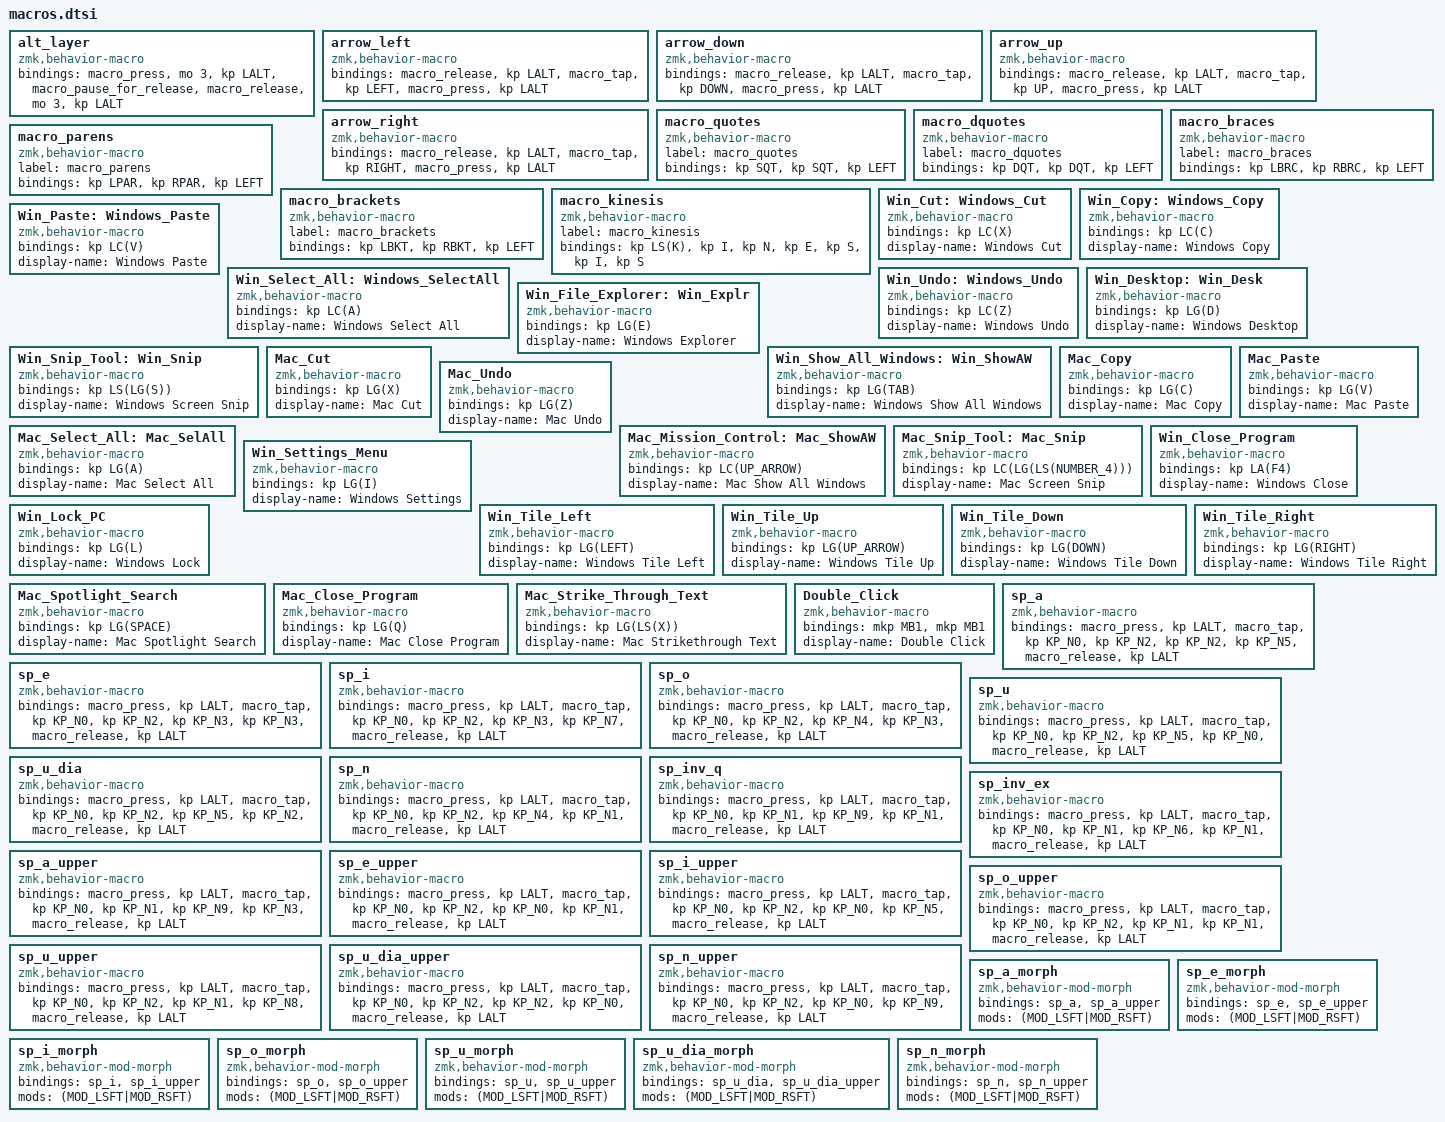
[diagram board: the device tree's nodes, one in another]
  // Alt + Layer 3 macro (holds Alt while layer is active)
  alt_layer: alt_layer {
    compatible = "zmk,behavior-macro";
    #binding-cells = <0>;
    bindings = <&macro_press &mo 3 &kp LALT>, <&macro_pause_for_release>, <&macro_release &mo 3 &kp LALT>;
  };

  // Arrow macros that release Alt, tap arrow, re-press Alt (for vim-style navigation)
  arrow_left: arrow_left {
    compatible = "zmk,behavior-macro";
    #binding-cells = <0>;
    bindings = <&macro_release &kp LALT>, <&macro_tap &kp LEFT>, <&macro_press &kp LALT>;
  };

  arrow_down: arrow_down {
    compatible = "zmk,behavior-macro";
    #binding-cells = <0>;
    bindings = <&macro_release &kp LALT>, <&macro_tap &kp DOWN>, <&macro_press &kp LALT>;
  };

  arrow_up: arrow_up {
    compatible = "zmk,behavior-macro";
    #binding-cells = <0>;
    bindings = <&macro_release &kp LALT>, <&macro_tap &kp UP>, <&macro_press &kp LALT>;
  };

  arrow_right: arrow_right {
    compatible = "zmk,behavior-macro";
    #binding-cells = <0>;
    bindings = <&macro_release &kp LALT>, <&macro_tap &kp RIGHT>, <&macro_press &kp LALT>;
  };

  macro_quotes: macro_quotes {
    compatible = "zmk,behavior-macro";
    label = "macro_quotes";
    #binding-cells = <0>;
    bindings = <&kp SQT>, <&kp SQT>, <&kp LEFT>;
  };
  macro_dquotes: macro_dquotes {
    compatible = "zmk,behavior-macro";
    label = "macro_dquotes";
    #binding-cells = <0>;
    bindings = <&kp DQT>, <&kp DQT>, <&kp LEFT>;
  };
  macro_braces: macro_braces {
    compatible = "zmk,behavior-macro";
    label = "macro_braces";
    #binding-cells = <0>;
    bindings = <&kp LBRC>, <&kp RBRC>, <&kp LEFT>;
  };
  macro_parens: macro_parens {
    compatible = "zmk,behavior-macro";
    label = "macro_parens";
    #binding-cells = <0>;
    bindings = <&kp LPAR>, <&kp RPAR>, <&kp LEFT>;
  };
  macro_brackets: macro_brackets {
    compatible = "zmk,behavior-macro";
    label = "macro_brackets";
    #binding-cells = <0>;
    bindings = <&kp LBKT>, <&kp RBKT>, <&kp LEFT>;
  };
  macro_kinesis: macro_kinesis {
    compatible = "zmk,behavior-macro";
    label = "macro_kinesis";
    #binding-cells = <0>;
    bindings = <&kp LS(K)>, <&kp I>, <&kp N>, <&kp E>, <&kp S>, <&kp I>, <&kp S>;
  };
  Win_Cut: Windows_Cut {
    compatible = "zmk,behavior-macro";
    #binding-cells = <0>;
    bindings = <&kp LC(X)>;
    display-name = "Windows Cut";
  };

  Win_Copy: Windows_Copy {
    compatible = "zmk,behavior-macro";
    #binding-cells = <0>;
    bindings = <&kp LC(C)>;
    display-name = "Windows Copy";
  };

  Win_Paste: Windows_Paste {
    compatible = "zmk,behavior-macro";
    #binding-cells = <0>;
    bindings = <&kp LC(V)>;
    display-name = "Windows Paste";
  };

  Win_Select_All: Windows_SelectAll {
      compatible = "zmk,behavior-macro";
      #binding-cells = <0>;
      bindings = <&kp LC(A)>;
      display-name = "Windows Select All";
  };

  Win_Undo: Windows_Undo {
    compatible = "zmk,behavior-macro";
    #binding-cells = <0>;
    bindings = <&kp LC(Z)>;
    display-name = "Windows Undo";
  };

  Win_Desktop: Win_Desk {
    compatible = "zmk,behavior-macro";
    #binding-cells = <0>;
    bindings = <&kp LG(D)>;
    display-name = "Windows Desktop";
  };

  Win_File_Explorer: Win_Explr {
    compatible = "zmk,behavior-macro";
    #binding-cells = <0>;
    bindings = <&kp LG(E)>;
    display-name = "Windows Explorer";
  };

  Win_Snip_Tool: Win_Snip {
    compatible = "zmk,behavior-macro";
    #binding-cells = <0>;
    bindings = <&kp LS(LG(S))>;
    display-name = "Windows Screen Snip";
  };

  Win_Show_All_Windows: Win_ShowAW {
    compatible = "zmk,behavior-macro";
    #binding-cells = <0>;
    bindings = <&kp LG(TAB)>;
    display-name = "Windows Show All Windows";
  };

  Mac_Cut: Mac_Cut {
    compatible = "zmk,behavior-macro";
    #binding-cells = <0>;
    bindings = <&kp LG(X)>;
    display-name = "Mac Cut";
  };

  Mac_Copy: Mac_Copy {
    compatible = "zmk,behavior-macro";
    #binding-cells = <0>;
    bindings = <&kp LG(C)>;
    display-name = "Mac Copy";
  };

  Mac_Paste: Mac_Paste {
    compatible = "zmk,behavior-macro";
    #binding-cells = <0>;
    bindings = <&kp LG(V)>;
    display-name = "Mac Paste";
  };

  Mac_Undo: Mac_Undo {
    compatible = "zmk,behavior-macro";
    #binding-cells = <0>;
    bindings = <&kp LG(Z)>;
    display-name = "Mac Undo";
  };

  Mac_Select_All: Mac_SelAll {
    compatible = "zmk,behavior-macro";
    #binding-cells = <0>;
    bindings = <&kp LG(A)>;
    display-name = "Mac Select All";
  };

  Mac_Mission_Control: Mac_ShowAW {
    compatible = "zmk,behavior-macro";
    #binding-cells = <0>;
    bindings = <&kp LC(UP_ARROW)>;
    display-name = "Mac Show All Windows";
  };

  Mac_Snip_Tool: Mac_Snip {
    compatible = "zmk,behavior-macro";
    #binding-cells = <0>;
    bindings = <&kp LC(LG(LS(NUMBER_4)))>;
    display-name = "Mac Screen Snip";
  };

  Win_Close_Program: Win_Close_Program {
    compatible = "zmk,behavior-macro";
    #binding-cells = <0>;
    bindings = <&kp LA(F4)>;
    display-name = "Windows Close";
  };

  Win_Settings_Menu: Win_Settings_Menu {
    compatible = "zmk,behavior-macro";
    #binding-cells = <0>;
    bindings = <&kp LG(I)>;
    display-name = "Windows Settings";
  };

  Win_Lock_PC: Win_Lock_PC {
    compatible = "zmk,behavior-macro";
    #binding-cells = <0>;
    bindings = <&kp LG(L)>;
    display-name = "Windows Lock";
  };

  Win_Tile_Left: Win_Tile_Left {
    compatible = "zmk,behavior-macro";
    #binding-cells = <0>;
    bindings = <&kp LG(LEFT)>;
    display-name = "Windows Tile Left";
  };

  Win_Tile_Up: Win_Tile_Up {
    compatible = "zmk,behavior-macro";
    #binding-cells = <0>;
    bindings = <&kp LG(UP_ARROW)>;
    display-name = "Windows Tile Up";
  };

  Win_Tile_Down: Win_Tile_Down {
    compatible = "zmk,behavior-macro";
    #binding-cells = <0>;
    bindings = <&kp LG(DOWN)>;
    display-name = "Windows Tile Down";
  };

  Win_Tile_Right: Win_Tile_Right {
    compatible = "zmk,behavior-macro";
    #binding-cells = <0>;
    bindings = <&kp LG(RIGHT)>;
    display-name = "Windows Tile Right";
  };

  Mac_Spotlight_Search: Mac_Spotlight_Search {
    compatible = "zmk,behavior-macro";
    #binding-cells = <0>;
    bindings = <&kp LG(SPACE)>;
    display-name = "Mac Spotlight Search";
  };

  Mac_Close_Program: Mac_Close_Program {
    compatible = "zmk,behavior-macro";
    #binding-cells = <0>;
    bindings = <&kp LG(Q)>;
    display-name = "Mac Close Program";
  };

  Mac_Strike_Through_Text: Mac_Strike_Through_Text {
    compatible = "zmk,behavior-macro";
    #binding-cells = <0>;
    bindings = <&kp LG(LS(X))>;
    display-name = "Mac Strikethrough Text";
  };

  Double_Click: Double_Click {
    compatible = "zmk,behavior-macro";
    #binding-cells = <0>;
    bindings = <&mkp MB1 &mkp MB1>;
    display-name = "Double Click";
  };

  // Spanish Alt codes (Windows numpad)
  sp_a: sp_a {
    compatible = "zmk,behavior-macro";
    #binding-cells = <0>;
    bindings = <&macro_press &kp LALT>, <&macro_tap &kp KP_N0 &kp KP_N2 &kp KP_N2 &kp KP_N5>, <&macro_release &kp LALT>;
  };

  sp_e: sp_e {
    compatible = "zmk,behavior-macro";
    #binding-cells = <0>;
    bindings = <&macro_press &kp LALT>, <&macro_tap &kp KP_N0 &kp KP_N2 &kp KP_N3 &kp KP_N3>, <&macro_release &kp LALT>;
  };

  sp_i: sp_i {
    compatible = "zmk,behavior-macro";
    #binding-cells = <0>;
    bindings = <&macro_press &kp LALT>, <&macro_tap &kp KP_N0 &kp KP_N2 &kp KP_N3 &kp KP_N7>, <&macro_release &kp LALT>;
  };

  sp_o: sp_o {
    compatible = "zmk,behavior-macro";
    #binding-cells = <0>;
    bindings = <&macro_press &kp LALT>, <&macro_tap &kp KP_N0 &kp KP_N2 &kp KP_N4 &kp KP_N3>, <&macro_release &kp LALT>;
  };

  sp_u: sp_u {
    compatible = "zmk,behavior-macro";
    #binding-cells = <0>;
    bindings = <&macro_press &kp LALT>, <&macro_tap &kp KP_N0 &kp KP_N2 &kp KP_N5 &kp KP_N0>, <&macro_release &kp LALT>;
  };

  sp_u_dia: sp_u_dia {
    compatible = "zmk,behavior-macro";
    #binding-cells = <0>;
    bindings = <&macro_press &kp LALT>, <&macro_tap &kp KP_N0 &kp KP_N2 &kp KP_N5 &kp KP_N2>, <&macro_release &kp LALT>;
  };

  sp_n: sp_n {
    compatible = "zmk,behavior-macro";
    #binding-cells = <0>;
    bindings = <&macro_press &kp LALT>, <&macro_tap &kp KP_N0 &kp KP_N2 &kp KP_N4 &kp KP_N1>, <&macro_release &kp LALT>;
  };

  sp_inv_q: sp_inv_q {
    compatible = "zmk,behavior-macro";
    #binding-cells = <0>;
    bindings = <&macro_press &kp LALT>, <&macro_tap &kp KP_N0 &kp KP_N1 &kp KP_N9 &kp KP_N1>, <&macro_release &kp LALT>;
  };

  sp_inv_ex: sp_inv_ex {
    compatible = "zmk,behavior-macro";
    #binding-cells = <0>;
    bindings = <&macro_press &kp LALT>, <&macro_tap &kp KP_N0 &kp KP_N1 &kp KP_N6 &kp KP_N1>, <&macro_release &kp LALT>;
  };

  // Uppercase Spanish letters (renamed to avoid case-insensitive collision)
  sp_a_upper: sp_a_upper {
    compatible = "zmk,behavior-macro";
    #binding-cells = <0>;
    bindings = <&macro_press &kp LALT>, <&macro_tap &kp KP_N0 &kp KP_N1 &kp KP_N9 &kp KP_N3>, <&macro_release &kp LALT>;
  };

  sp_e_upper: sp_e_upper {
    compatible = "zmk,behavior-macro";
    #binding-cells = <0>;
    bindings = <&macro_press &kp LALT>, <&macro_tap &kp KP_N0 &kp KP_N2 &kp KP_N0 &kp KP_N1>, <&macro_release &kp LALT>;
  };

  sp_i_upper: sp_i_upper {
    compatible = "zmk,behavior-macro";
    #binding-cells = <0>;
    bindings = <&macro_press &kp LALT>, <&macro_tap &kp KP_N0 &kp KP_N2 &kp KP_N0 &kp KP_N5>, <&macro_release &kp LALT>;
  };

  sp_o_upper: sp_o_upper {
    compatible = "zmk,behavior-macro";
    #binding-cells = <0>;
    bindings = <&macro_press &kp LALT>, <&macro_tap &kp KP_N0 &kp KP_N2 &kp KP_N1 &kp KP_N1>, <&macro_release &kp LALT>;
  };

  sp_u_upper: sp_u_upper {
    compatible = "zmk,behavior-macro";
    #binding-cells = <0>;
    bindings = <&macro_press &kp LALT>, <&macro_tap &kp KP_N0 &kp KP_N2 &kp KP_N1 &kp KP_N8>, <&macro_release &kp LALT>;
  };

  sp_u_dia_upper: sp_u_dia_upper {
    compatible = "zmk,behavior-macro";
    #binding-cells = <0>;
    bindings = <&macro_press &kp LALT>, <&macro_tap &kp KP_N0 &kp KP_N2 &kp KP_N2 &kp KP_N0>, <&macro_release &kp LALT>;
  };

  sp_n_upper: sp_n_upper {
    compatible = "zmk,behavior-macro";
    #binding-cells = <0>;
    bindings = <&macro_press &kp LALT>, <&macro_tap &kp KP_N0 &kp KP_N2 &kp KP_N0 &kp KP_N9>, <&macro_release &kp LALT>;
  };

  // Mod-morph behaviors (lowercase / uppercase with Shift)
  sp_a_morph: sp_a_morph {
    compatible = "zmk,behavior-mod-morph";
    #binding-cells = <0>;
    bindings = <&sp_a>, <&sp_a_upper>;
    mods = <(MOD_LSFT|MOD_RSFT)>;
  };

  sp_e_morph: sp_e_morph {
    compatible = "zmk,behavior-mod-morph";
    #binding-cells = <0>;
    bindings = <&sp_e>, <&sp_e_upper>;
    mods = <(MOD_LSFT|MOD_RSFT)>;
  };

  sp_i_morph: sp_i_morph {
    compatible = "zmk,behavior-mod-morph";
    #binding-cells = <0>;
    bindings = <&sp_i>, <&sp_i_upper>;
    mods = <(MOD_LSFT|MOD_RSFT)>;
  };

  sp_o_morph: sp_o_morph {
    compatible = "zmk,behavior-mod-morph";
    #binding-cells = <0>;
    bindings = <&sp_o>, <&sp_o_upper>;
    mods = <(MOD_LSFT|MOD_RSFT)>;
  };

  sp_u_morph: sp_u_morph {
    compatible = "zmk,behavior-mod-morph";
    #binding-cells = <0>;
    bindings = <&sp_u>, <&sp_u_upper>;
    mods = <(MOD_LSFT|MOD_RSFT)>;
  };

  sp_u_dia_morph: sp_u_dia_morph {
    compatible = "zmk,behavior-mod-morph";
    #binding-cells = <0>;
    bindings = <&sp_u_dia>, <&sp_u_dia_upper>;
    mods = <(MOD_LSFT|MOD_RSFT)>;
  };

  sp_n_morph: sp_n_morph {
    compatible = "zmk,behavior-mod-morph";
    #binding-cells = <0>;
    bindings = <&sp_n>, <&sp_n_upper>;
    mods = <(MOD_LSFT|MOD_RSFT)>;
  };

